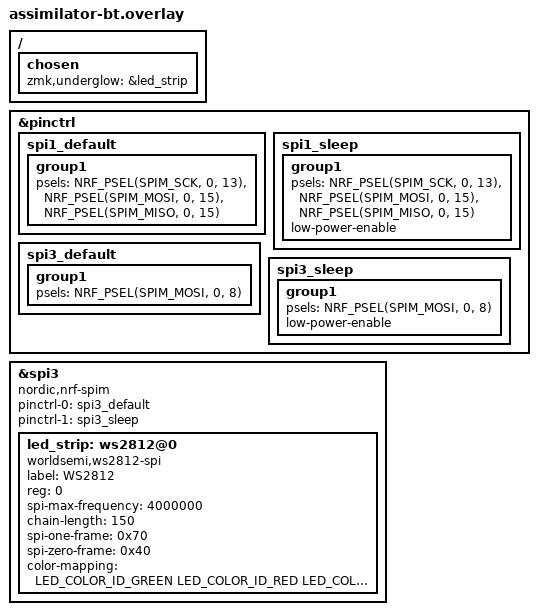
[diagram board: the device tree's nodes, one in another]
// The assimilator-bt board dts wires &spi1 to the spi1_default/spi1_sleep
// pinctrl labels but leaves their definition to the shield (the imprint
// shield's per-board overlay provides them). Provide them here too so the
// dongle shield builds standalone on this board; the SPI bus stays unused
// (no trackball on a dongle).
//
// The RGB strip (spi3) is wired the same as the imprint shield's per-board
// overlay: this board is a keyboard PCB with underglow LEDs, and the dongle
// (as split central) is also what dispatches &rgb_ug to the halves. Every
// dongle board overlay must define a strip + zmk,underglow chosen —
// ZMK_RGB_UNDERGLOW defaults y module-wide and rgb_underglow.c won't
// compile without one (see the xiao_ble overlay).

#include <dt-bindings/led/led.h>

&pinctrl {
    spi1_default: spi1_default {
        group1 {
            psels = <NRF_PSEL(SPIM_SCK, 0, 13)>,
                <NRF_PSEL(SPIM_MOSI, 0, 15)>,
                <NRF_PSEL(SPIM_MISO, 0, 15)>;
        };
    };

    spi1_sleep: spi1_sleep {
        group1 {
            psels = <NRF_PSEL(SPIM_SCK, 0, 13)>,
                <NRF_PSEL(SPIM_MOSI, 0, 15)>,
                <NRF_PSEL(SPIM_MISO, 0, 15)>;
            low-power-enable;
        };
    };

    spi3_default: spi3_default {
        group1 {
            psels = <NRF_PSEL(SPIM_MOSI, 0, 8)>;
        };
    };

    spi3_sleep: spi3_sleep {
        group1 {
            psels = <NRF_PSEL(SPIM_MOSI, 0, 8)>;
            low-power-enable;
        };
    };
};

&spi3 {
    compatible = "nordic,nrf-spim";
    status = "okay";

    pinctrl-0 = <&spi3_default>;
    pinctrl-1 = <&spi3_sleep>;
    pinctrl-names = "default", "sleep";

    led_strip: ws2812@0 {
        compatible = "worldsemi,ws2812-spi";
        label = "WS2812";

        /* SPI */
        reg = <0>; /* ignored, but necessary for SPI bindings */
        spi-max-frequency = <4000000>;

        /* WS2812 */
        chain-length = <150>; /* arbitrary; change at will */
        spi-one-frame = <0x70>;
        spi-zero-frame = <0x40>;

        color-mapping = <LED_COLOR_ID_GREEN LED_COLOR_ID_RED LED_COLOR_ID_BLUE>;
    };
};

/ {
    chosen {
        zmk,underglow = &led_strip;
    };
};
